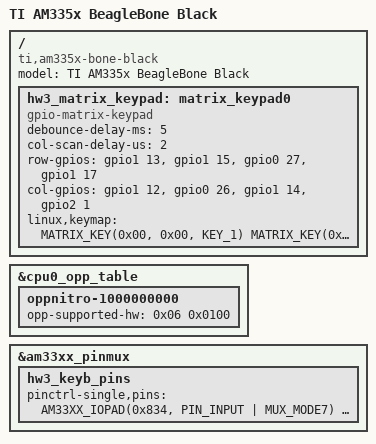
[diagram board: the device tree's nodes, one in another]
/*
 * Copyright (C) 2012 Texas Instruments Incorporated - http://www.ti.com/
 *
 * This program is free software; you can redistribute it and/or modify
 * it under the terms of the GNU General Public License version 2 as
 * published by the Free Software Foundation.
 */
/dts-v1/;

#include <dt-bindings/input/input.h>
#include "am33xx.dtsi"
#include "am335x-bone-common.dtsi"
#include "am335x-boneblack-common.dtsi"
#include <dt-bindings/gpio/gpio.h>
#include <dt-bindings/pinctrl/am33xx.h>

/ {
	model = "TI AM335x BeagleBone Black";
	compatible = "ti,am335x-bone-black", "ti,am335x-bone", "ti,am33xx";

};

&cpu0_opp_table {
	/*
	 * All PG 2.0 silicon may not support 1GHz but some of the early
	 * BeagleBone Blacks have PG 2.0 silicon which is guaranteed
	 * to support 1GHz OPP so enable it for PG 2.0 on this board.
	 */
	oppnitro-1000000000 {
		opp-supported-hw = <0x06 0x0100>;
	};
};


&am33xx_pinmux {
    /*
     * Keyboard lines:
     * Scan
     * GPIO_1_12 (GPMC_AD12) - 0x830
     * GPIO_0_26 (GPMC_AD10) - 0x828
     * GPIO_1_14 (GPMC_AD14) - 0x838
     * GPIO_2_1  (GPMC_CLK)  - 0x88c
     * Read
     * GPIO_1_13 (GPMC_AD13) - 0x834
     * GPIO_1_15 (GPMC_AD15) - 0x83c
     * GPIO_0_27 (GPMC_AD11) - 0x82c
     * GPIO_1_17 (GPMC_A1)   - 0x844
     *
     */

    hw3_keyb_pins: hw3_keyb_pins {
		pinctrl-single,pins = <
			AM33XX_IOPAD(0x834, PIN_INPUT | MUX_MODE7)	
			AM33XX_IOPAD(0x83c, PIN_INPUT | MUX_MODE7)	
			AM33XX_IOPAD(0x82c, PIN_INPUT | MUX_MODE7)	
			AM33XX_IOPAD(0x844, PIN_INPUT | MUX_MODE7)
            
			AM33XX_IOPAD(0x830, PIN_OUTPUT | MUX_MODE7)	
			AM33XX_IOPAD(0x828, PIN_OUTPUT | MUX_MODE7)	
			AM33XX_IOPAD(0x838, PIN_OUTPUT | MUX_MODE7)	
			AM33XX_IOPAD(0x88c, PIN_OUTPUT | MUX_MODE7)	
		>;
	};
};


/{
    hw3_matrix_keypad: matrix_keypad0 {
                compatible = "gpio-matrix-keypad";
                debounce-delay-ms = <5>;
                col-scan-delay-us = <2>;
                
                row-gpios = <&gpio1 13 GPIO_ACTIVE_HIGH     
                             &gpio1 15 GPIO_ACTIVE_HIGH     
                             &gpio0 27 GPIO_ACTIVE_HIGH
                             &gpio1 17 GPIO_ACTIVE_HIGH>;   
                
                col-gpios = <&gpio1 12 GPIO_ACTIVE_HIGH
                             &gpio0 26 GPIO_ACTIVE_HIGH
                             &gpio1 14 GPIO_ACTIVE_HIGH
                             &gpio2 1  GPIO_ACTIVE_HIGH>;   
                linux,keymap = < MATRIX_KEY(0x00, 0x00, KEY_1)
                                 MATRIX_KEY(0x00, 0x01, KEY_2)
                                 MATRIX_KEY(0x00, 0x02, KEY_3)
                                 MATRIX_KEY(0x00, 0x03, KEY_A)
                                 MATRIX_KEY(0x01, 0x00, KEY_4)
                                 MATRIX_KEY(0x01, 0x01, KEY_5)
                                 MATRIX_KEY(0x01, 0x02, KEY_6)
                                 MATRIX_KEY(0x01, 0x03, KEY_B)
                                 MATRIX_KEY(0x02, 0x00, KEY_7)
                                 MATRIX_KEY(0x02, 0x01, KEY_8)
                                 MATRIX_KEY(0x02, 0x02, KEY_9)
                                 MATRIX_KEY(0x02, 0x03, KEY_C)
                                 MATRIX_KEY(0x03, 0x00, KEY_TAB)
                                 MATRIX_KEY(0x03, 0x01, KEY_0)
                                 MATRIX_KEY(0x03, 0x02, KEY_ENTER)
                                 MATRIX_KEY(0x03, 0x03, KEY_D)
                         >;
        };
}; 

